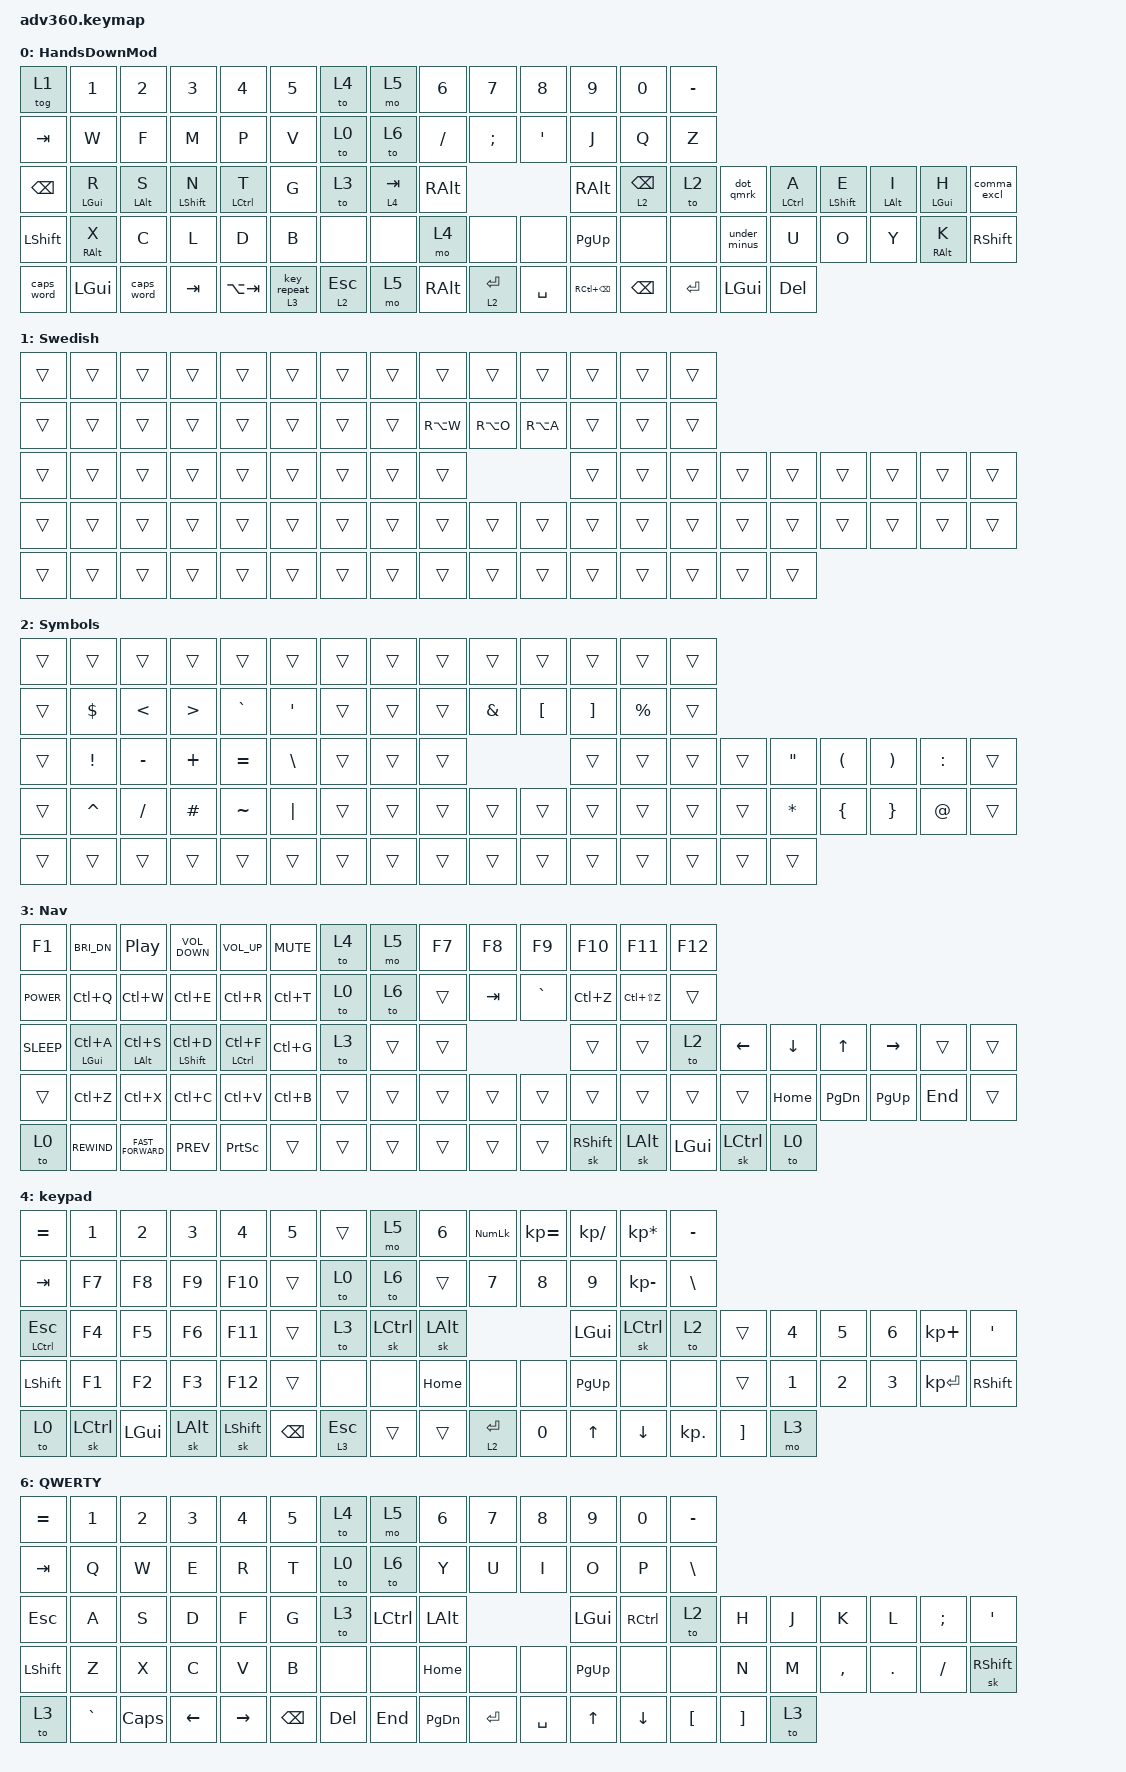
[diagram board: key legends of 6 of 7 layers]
#include <behaviors.dtsi>
#include <dt-bindings/led/led.h>
#include <dt-bindings/zmk/backlight.h>
#include <dt-bindings/zmk/bt.h>
#include <dt-bindings/zmk/keys.h>
#include <dt-bindings/zmk/rgb.h>

/ {
    behaviors {
        #include "macros.dtsi"

        gqt: global-quick-tap {
            compatible = "zmk,behavior-hold-tap";
            label = "GLOBAL_QUICK_TAP";
            #binding-cells = <2>;
            flavor = "tap-preferred";
            tapping-term-ms = <225>;
            quick-tap-ms = <200>;
            global-quick-tap;
            bindings =
                <&kp>,
                <&kp>;
        };
        gql: global-quick-tap-layer {
            compatible = "zmk,behavior-hold-tap";
            label = "GLOBAL_QUICK_TAP_LAYER";
            #binding-cells = <2>;
            flavor = "tap-preferred";
            tapping-term-ms = <225>;
            quick-tap-ms = <200>;
            global-quick-tap;
            bindings =
                <&mo>,
                <&kp>;
        };
        gqr: global-quick-tap-layer-repeat {
            compatible = "zmk,behavior-hold-tap";
            label = "GLOBAL_QUICK_TAP_LAYER_REPEAT";
            #binding-cells = <2>;
            flavor = "tap-preferred";
            tapping-term-ms = <225>;
            quick-tap-ms = <200>;
            global-quick-tap;
            bindings =
                <&mo>,
                <&key_repeat>;
        };
        dot_qmrk: dot_qmrk {
            compatible = "zmk,behavior-mod-morph";
            label = "dot_qmrk";
            #binding-cells = <0>;
            bindings =
                <&kp DOT>,
                <&kp QUESTION>;

            mods = <(MOD_LSFT|MOD_RSFT)>;
        };
        comma_excl: comma_excl {
            compatible = "zmk,behavior-mod-morph";
            label = "comma_excl";
            #binding-cells = <0>;
            bindings =
                <&kp COMMA>,
                <&kp EXCL>;

            mods = <(MOD_LSFT|MOD_RSFT)>;
        };
        lpar_bsh: lpar_bsh {
            compatible = "zmk,behavior-mod-morph";
            label = "lpar_bsh";
            #binding-cells = <0>;
            bindings =
                <&kp LEFT_PARENTHESIS>,
                <&kp BACKSLASH>;

            mods = <(MOD_LSFT|MOD_RSFT)>;
        };
        rpar_fsh: rpar_fsh {
            compatible = "zmk,behavior-mod-morph";
            label = "rpar_fsh";
            #binding-cells = <0>;
            bindings =
                <&kp RIGHT_PARENTHESIS>,
                <&kp SLASH>;

            mods = <(MOD_LSFT|MOD_RSFT)>;
        };
        under_minus: under_minus {
            compatible = "zmk,behavior-mod-morph";
            label = "under_minus";
            #binding-cells = <0>;
            bindings =
                <&kp UNDERSCORE>,
                <&kp MINUS>;

            mods = <(MOD_LSFT|MOD_RSFT)>;
        };
    };

    keymap {
        compatible = "zmk,keymap";

        HandsDownMod {
            bindings = <
        &tog 1           &kp N1           &kp N2             &kp N3               &kp N4    &kp N5         &to 4       &mo 5     &kp N6        &kp N7            &kp N8             &kp N9            &kp N0  &kp MINUS
       &kp TAB            &kp W            &kp F              &kp M                &kp P     &kp V         &to 0       &to 6  &kp SLASH      &kp SEMI  &kp SINGLE_QUOTE              &kp J             &kp Q      &kp Z
 &kp BACKSPACE  &gqt LEFT_GUI R  &gqt LEFT_ALT S  &gqt LEFT_SHIFT N  &gqt LEFT_CONTROL T     &kp G         &to 3  &gql 4 TAB   &kp RALT                                           &kp RALT  &gql 2 BACKSPACE      &to 2     &dot_qmrk  &gqt LEFT_CONTROL A  &gqt LEFT_SHIFT E  &gqt LEFT_ALT I  &gqt LEFT_GUI H      &comma_excl
&kp LEFT_SHIFT      &gqt RALT X            &kp C              &kp L                &kp D     &kp B         &none       &none      &mo 4         &none             &none          &kp PG_UP             &none      &none  &under_minus                &kp U              &kp O            &kp Y      &gqt RALT K  &kp RIGHT_SHIFT
    &caps_word     &kp LEFT_GUI       &caps_word            &kp TAB          &kp LA(TAB)  &gqr 3 0  &lt 2 ESCAPE       &mo 5   &kp RALT  &gql 2 ENTER         &kp SPACE  &kp RC(BACKSPACE)     &kp BACKSPACE  &kp ENTER  &kp LEFT_GUI           &kp DELETE
            >;
        };

        Swedish {
            bindings = <
&trans  &trans  &trans  &trans  &trans  &trans  &trans  &trans     &trans     &trans     &trans  &trans  &trans  &trans
&trans  &trans  &trans  &trans  &trans  &trans  &trans  &trans  &kp RA(W)  &kp RA(O)  &kp RA(A)  &trans  &trans  &trans
&trans  &trans  &trans  &trans  &trans  &trans  &trans  &trans     &trans                        &trans  &trans  &trans  &trans  &trans  &trans  &trans  &trans  &trans
&trans  &trans  &trans  &trans  &trans  &trans  &trans  &trans     &trans     &trans     &trans  &trans  &trans  &trans  &trans  &trans  &trans  &trans  &trans  &trans
&trans  &trans  &trans  &trans  &trans  &trans  &trans  &trans     &trans     &trans     &trans  &trans  &trans  &trans  &trans  &trans
            >;
        };

        Symbols {
            bindings = <
&trans           &trans         &trans            &trans     &trans            &trans  &trans  &trans  &trans         &trans            &trans             &trans       &trans  &trans
&trans       &kp DOLLAR  &kp LESS_THAN  &kp GREATER_THAN  &kp GRAVE  &kp SINGLE_QUOTE  &trans  &trans  &trans  &kp AMPERSAND  &kp LEFT_BRACKET  &kp RIGHT_BRACKET  &kp PERCENT  &trans
&trans  &kp EXCLAMATION      &kp MINUS          &kp PLUS  &kp EQUAL     &kp BACKSLASH  &trans  &trans  &trans                                              &trans       &trans  &trans  &trans  &kp DOUBLE_QUOTES  &kp LEFT_PARENTHESIS  &kp RIGHT_PARENTHESIS  &kp COLON  &trans
&trans        &kp CARET      &kp SLASH          &kp HASH  &kp TILDE          &kp PIPE  &trans  &trans  &trans         &trans            &trans             &trans       &trans  &trans  &trans       &kp ASTERISK        &kp LEFT_BRACE        &kp RIGHT_BRACE     &kp AT  &trans
&trans           &trans         &trans            &trans     &trans            &trans  &trans  &trans  &trans         &trans            &trans             &trans       &trans  &trans  &trans             &trans
            >;
        };

        Nav {
            bindings = <
     &kp F1        &kp C_BRI_DN    &kp C_PLAY_PAUSE  &kp C_VOLUME_DOWN  &kp C_VOLUME_UP  &kp K_MUTE   &to 4   &mo 5  &kp F7   &kp F8     &kp F9          &kp F10        &kp F11       &kp F12
&kp C_POWER           &kp LC(Q)           &kp LC(W)          &kp LC(E)        &kp LC(R)   &kp LC(T)   &to 0   &to 6  &trans  &kp TAB  &kp GRAVE        &kp LC(Z)  &kp LC(LS(Z))        &trans
&kp C_SLEEP  &mt LEFT_GUI LC(A)      &mt LALT LC(S)   &mt LSHIFT LC(D)  &mt LCTRL LC(F)   &kp LC(G)   &to 3  &trans  &trans                               &trans         &trans         &to 2          &kp LEFT  &kp DOWN         &kp UP    &kp RIGHT   &trans  &trans
     &trans           &kp LC(Z)           &kp LC(X)          &kp LC(C)        &kp LC(V)   &kp LC(B)  &trans  &trans  &trans   &trans     &trans           &trans         &trans        &trans            &trans  &kp HOME  &kp PAGE_DOWN  &kp PAGE_UP  &kp END  &trans
      &to 0        &kp C_REWIND  &kp C_FAST_FORWARD         &kp C_PREV  &kp PRINTSCREEN      &trans  &trans  &trans  &trans   &trans     &trans  &sk RIGHT_SHIFT   &sk LEFT_ALT  &kp LEFT_GUI  &sk LEFT_CONTROL     &to 0
            >;
        };

        keypad {
            bindings = <
           &kp EQUAL            &kp N1        &kp N2        &kp N3          &kp N4         &kp N5     &trans             &mo 5        &kp N6   &kp KP_NUM  &kp KP_EQUAL  &kp KP_DIVIDE   &kp KP_MULTIPLY   &kp MINUS
             &kp TAB            &kp F7        &kp F8        &kp F9         &kp F10         &trans      &to 0             &to 6        &trans       &kp N7        &kp N8         &kp N9      &kp KP_MINUS    &kp BSLH
&mt LEFT_CONTROL ESC            &kp F4        &kp F5        &kp F6         &kp F11         &trans      &to 3  &sk LEFT_CONTROL  &sk LEFT_ALT                              &kp LEFT_GUI  &sk LEFT_CONTROL       &to 2    &trans  &kp N4  &kp N5  &kp N6   &kp KP_PLUS    &kp SQT
      &kp LEFT_SHIFT            &kp F1        &kp F2        &kp F3         &kp F12         &trans      &none             &none      &kp HOME        &none         &none      &kp PG_UP             &none       &none    &trans  &kp N1  &kp N2  &kp N3  &kp KP_ENTER  &kp RSHFT
               &to 0  &sk LEFT_CONTROL  &kp LEFT_GUI  &sk LEFT_ALT  &sk LEFT_SHIFT  &kp BACKSPACE  &lt 3 ESC            &trans        &trans  &lt 2 ENTER        &kp N0         &kp UP          &kp DOWN  &kp KP_DOT  &kp RBKT   &mo 3
            >;
        };

        mod {
            bindings = <
&none &bt BT_SEL 0 &bt BT_SEL 1 &bt BT_SEL 2 &bt BT_SEL 3 &bt BT_SEL 4 &none                                                               &trans      &none &none      &none      &none &none &none
&none &none        &none        &none        &none        &none        &bootloader                                                         &bootloader &none &none      &none      &none &none &none
&none &none        &none        &none        &none        &none        &none             &none &none &bt BT_CLR &none                      &none       &none &none      &none      &none &none &none
&none &none        &none        &none        &none        &none                                &none &none                                             &none &none      &none      &none &none &none
&none &none        &none        &none        &none                                 &none &none &none &none      &bl BL_TOG &rgb_ug RGB_TOG                   &bl BL_INC &bl BL_DEC &none &none &none
            >;
        };

        QWERTY {
            bindings = <
     &kp EQUAL  &kp NUMBER_1  &kp NUMBER_2  &kp NUMBER_3  &kp NUMBER_4   &kp NUMBER_5       &to 4      &mo 5  &kp NUMBER_6  &kp NUMBER_7  &kp NUMBER_8  &kp NUMBER_9  &kp NUMBER_0         &kp MINUS
       &kp TAB         &kp Q         &kp W         &kp E         &kp R          &kp T       &to 0      &to 6         &kp Y         &kp U         &kp I         &kp O         &kp P     &kp BACKSLASH
    &kp ESCAPE         &kp A         &kp S         &kp D         &kp F          &kp G       &to 3  &kp LCTRL      &kp LALT                              &kp LEFT_GUI     &kp RCTRL             &to 2              &kp H  &kp J      &kp K    &kp L   &kp SEMI  &kp SINGLE_QUOTE
&kp LEFT_SHIFT         &kp Z         &kp X         &kp C         &kp V          &kp B       &none      &none      &kp HOME         &none         &none     &kp PG_UP         &none             &none              &kp N  &kp M  &kp COMMA  &kp DOT  &kp SLASH   &sk RIGHT_SHIFT
         &to 3     &kp GRAVE  &kp CAPSLOCK      &kp LEFT     &kp RIGHT  &kp BACKSPACE  &kp DELETE    &kp END     &kp PG_DN     &kp ENTER     &kp SPACE        &kp UP      &kp DOWN  &kp LEFT_BRACKET  &kp RIGHT_BRACKET  &to 3
            >;
        };
    };
};
